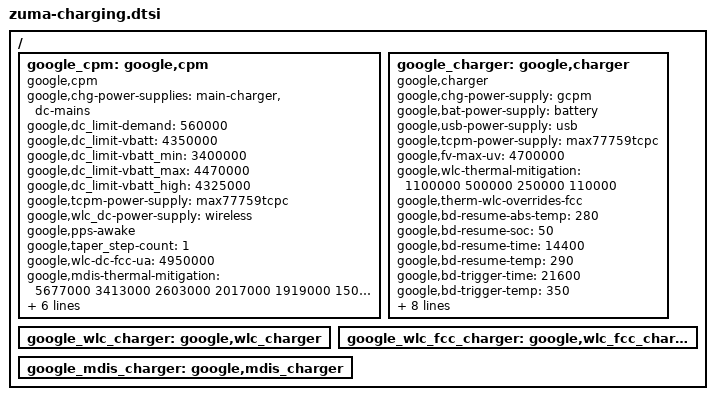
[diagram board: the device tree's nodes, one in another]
// SPDX-License-Identifier: GPL-2.0-only
/*
 * Zuma common Battery device tree entries
 *
 * Copyright 2023 Google LLC
 *
 */

/ {
	fragment@charging {
		target-path = "/";
		__overlay__ {

			google_cpm: google,cpm {
				status = "okay";
				compatible = "google,cpm";
				#cooling-cells = <2>;

				google,chg-power-supplies = "main-charger",	// out-0
							    "dc-mains";	// out-1

				google,dc_limit-demand = <560000>;
				google,dc_limit-vbatt = <4350000>;
				google,dc_limit-vbatt_min = <3400000>;
				google,dc_limit-vbatt_max = <4470000>;
				google,dc_limit-vbatt_high = <4325000>;

				google,tcpm-power-supply = <&max77759tcpc>;	// in=0
				google,wlc_dc-power-supply = "wireless";	// in=1
				google,pps-awake;

				google,taper_step-count = <1>;
				google,wlc-dc-fcc-ua = <4950000>; /* 1C(4950mah) */

				// thermal budgets
				google,mdis-thermal-mitigation =
				<5677000 3413000 2603000 2017000 1919000 1506000  909000  575000  254000>;
				// source ONLINE selection criteria
				google,mdis-out-sel-online = <1 2>;
				// PD+main-charger, WLC+main-charger
				google,mdis-out0-limits =
				<4000000 3500000 3000000 3000000 2500000 2000000 1500000 1000000   500000
				 1100000  500000  500000  500000  250000  250000  100000  100000   100000>;
				// PPS_CP+pca94xx-mains, // WLC_CP+pca94xx-mains
				google,mdis-out1-limits =
				<6000000  5500000 5000000 4500000 3500000 3000000 2500000 2000000 1000000
				 5000000  4500000 4000000 3000000 2500000 2000000 1500000 1000000       0>;

				google,no-init-wlc-ta-vol;
			};

			google_charger: google,charger {
				status = "okay";
				compatible = "google,charger";
				#cooling-cells = <2>;

				google,chg-power-supply = "gcpm";
				google,bat-power-supply = "battery";
				google,usb-power-supply = "usb";
				google,tcpm-power-supply = <&max77759tcpc>;

				google,fv-max-uv = <4700000>;

				google,wlc-thermal-mitigation = <1100000 500000 250000 110000>;
				google,therm-wlc-overrides-fcc;

				/* b/170700459 thresholds, updated in b/191070950 */
				google,bd-resume-abs-temp = <280>;
				google,bd-resume-soc = <50>;
				google,bd-resume-time = <14400>;  /* 4 hours */
				google,bd-resume-temp = <290>;
				google,bd-trigger-time = <21600>; /* 6 hours */
				google,bd-trigger-temp = <350>;
				google,bd-trigger-voltage = <4270000>;
				google,bd-recharge-voltage = <4250000>;
				google,bd-drainto-soc = <80>;
				google,bd-recharge-soc = <79>;
				/* Enable TEMP-DEFEND */
				google,bd-temp-enable;
				google,bd-temp-dry-run;

				google,chg-termination-5v;
				google,chg-taper-last-tier;
			};

			google_wlc_charger: google,wlc_charger {
				#cooling-cells = <2>;
			};

			google_wlc_fcc_charger: google,wlc_fcc_charger {
				#cooling-cells = <2>;
			};

			google_mdis_charger: google,mdis_charger {
				#cooling-cells = <2>;
			};

		};
	};
};
